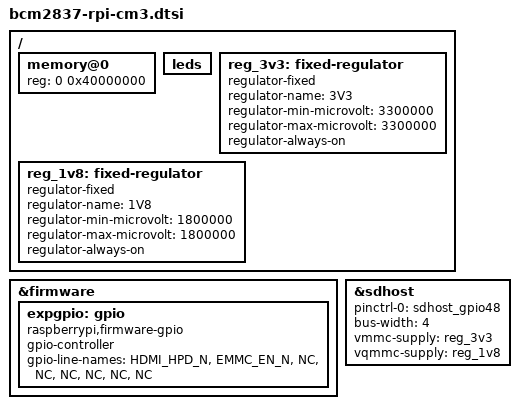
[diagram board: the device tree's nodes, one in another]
// SPDX-License-Identifier: GPL-2.0
/dts-v1/;
#include "bcm2837.dtsi"
#include "bcm2836-rpi.dtsi"

/ {
	memory@0 {
		device_type = "memory";
		reg = <0 0x40000000>;
	};

	leds {
		/*
		 * Since there is no upstream GPIO driver yet,
		 * remove the incomplete node.
		 */
		/delete-node/ act;
	};

	reg_3v3: fixed-regulator {
		compatible = "regulator-fixed";
		regulator-name = "3V3";
		regulator-min-microvolt = <3300000>;
		regulator-max-microvolt = <3300000>;
		regulator-always-on;
	};

	reg_1v8: fixed-regulator {
		compatible = "regulator-fixed";
		regulator-name = "1V8";
		regulator-min-microvolt = <1800000>;
		regulator-max-microvolt = <1800000>;
		regulator-always-on;
	};
};

&firmware {
	expgpio: gpio {
		compatible = "raspberrypi,firmware-gpio";
		gpio-controller;
		#gpio-cells = <2>;
		gpio-line-names = "HDMI_HPD_N",
				  "EMMC_EN_N",
				  "NC",
				  "NC",
				  "NC",
				  "NC",
				  "NC",
				  "NC";
		status = "okay";
	};
};

&sdhost {
	pinctrl-names = "default";
	pinctrl-0 = <&sdhost_gpio48>;
	bus-width = <4>;
	vmmc-supply = <&reg_3v3>;
	vqmmc-supply = <&reg_1v8>;
	status = "okay";
};
